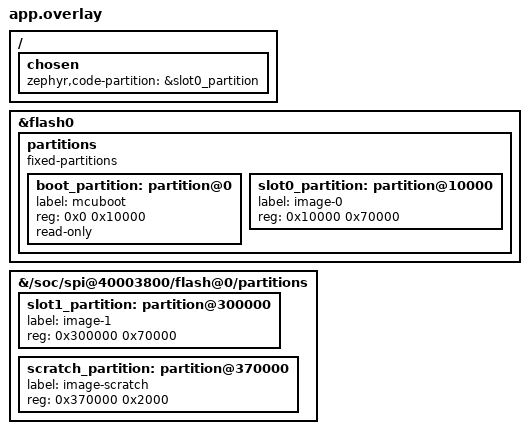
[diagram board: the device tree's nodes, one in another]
/* MCUboot profile only. It cannot be booted by the legacy 16 KiB BOOT. */
/ {
    chosen { zephyr,code-partition = &slot0_partition; };
};
&flash0 {
    /delete-node/ partitions;
    partitions {
        compatible = "fixed-partitions";
        #address-cells = <1>;
        #size-cells = <1>;
        boot_partition: partition@0 {
            label = "mcuboot";
            reg = <0x0 0x10000>;
            read-only;
        };
        slot0_partition: partition@10000 {
            label = "image-0";
            reg = <0x10000 0x70000>;
        };
    };
};
/* Keep old parameter/config/SGZ regions. Reuse only old BIN staging area. */
&{/soc/spi@40003800/flash@0/partitions} {
    /delete-node/ partition@300000;
    slot1_partition: partition@300000 {
        label = "image-1";
        reg = <0x300000 0x70000>;
    };
    scratch_partition: partition@370000 {
        label = "image-scratch";
        reg = <0x370000 0x2000>;
    };
};
